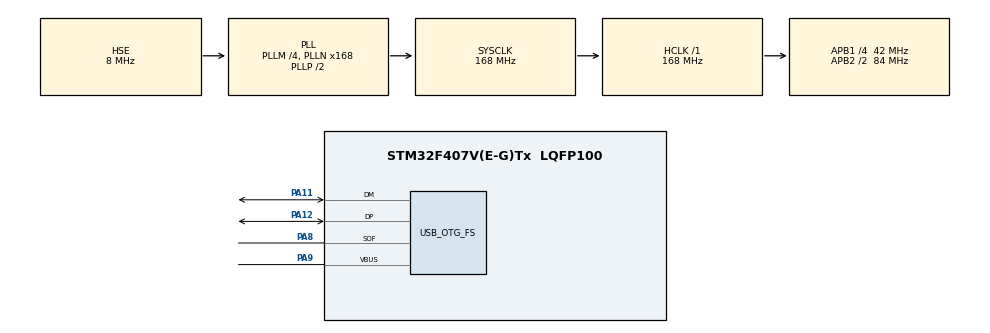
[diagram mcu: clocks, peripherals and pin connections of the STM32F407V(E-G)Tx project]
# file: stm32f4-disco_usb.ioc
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FREERTOS.Tasks01=defaultTask,24,128,StartDefaultTask,Default,NULL,Dynamic,NULL,NULL
FREERTOS.configENABLE_FPU=1
FREERTOS.configTOTAL_HEAP_SIZE=32768
FREERTOS.configUSE_NEWLIB_REENTRANT=1
Mcu.Family=STM32F4
Mcu.Name=STM32F407V(E-G)Tx
Mcu.Package=LQFP100
NVIC.OTG_FS_IRQn=true\:5\:0\:false\:false\:true\:true\:false\:true\:true
NVIC.PriorityGroup=NVIC_PRIORITYGROUP_4
NVIC.TIM1_UP_TIM10_IRQn=true\:15\:0\:false\:false\:true\:false\:false\:true\:true
NVIC.TimeBase=TIM1_UP_TIM10_IRQn
NVIC.TimeBaseIP=TIM1
PA11.Mode=Device_Only
PA11.Signal=USB_OTG_FS_DM
PA12.Mode=Device_Only
PA12.Signal=USB_OTG_FS_DP
PA13.Mode=Serial_Wire
PA13.Signal=SYS_JTMS-SWDIO
PA14.Mode=Serial_Wire
PA14.Signal=SYS_JTCK-SWCLK
PA8.Mode=Activate_SOF_FS
PA8.Signal=USB_OTG_FS_SOF
PA9.Mode=Activate_VBUS
PA9.Signal=USB_OTG_FS_VBUS
PH0-OSC_IN.Mode=HSE-External-Oscillator
PH0-OSC_IN.Signal=RCC_OSC_IN
PH1-OSC_OUT.Mode=HSE-External-Oscillator
PH1-OSC_OUT.Signal=RCC_OSC_OUT
ProjectManager.HeapSize=0x200
ProjectManager.StackSize=0x400
ProjectManager.TargetToolchain=STM32CubeIDE
RCC.48MHZClocksFreq_Value=48000000
RCC.AHBFreq_Value=168000000
RCC.APB1CLKDivider=RCC_HCLK_DIV4
RCC.APB1Freq_Value=42000000
RCC.APB1TimFreq_Value=84000000
RCC.APB2CLKDivider=RCC_HCLK_DIV2
RCC.APB2Freq_Value=84000000
RCC.APB2TimFreq_Value=168000000
RCC.CortexFreq_Value=168000000
RCC.HCLKFreq_Value=168000000
RCC.HSE_VALUE=8000000
RCC.HSI_VALUE=16000000
RCC.LSE_VALUE=32768
RCC.PLLM=4
RCC.PLLN=168
RCC.PLLQ=7
RCC.SYSCLKFreq_VALUE=168000000
RCC.SYSCLKSource=RCC_SYSCLKSOURCE_PLLCLK
RCC.VCOOutputFreq_Value=336000000
USB_DEVICE.CLASS_NAME_FS=CDC
USB_DEVICE.VirtualMode-CDC_FS=Cdc
USB_DEVICE.VirtualModeFS=Cdc_FS
USB_OTG_FS.VirtualMode=Device_Only
VP_FREERTOS_VS_CMSIS_V2.Mode=CMSIS_V2
VP_SYS_VS_tim1.Mode=TIM1
VP_USB_DEVICE_VS_USB_DEVICE_CDC_FS.Mode=CDC_FS
board=custom

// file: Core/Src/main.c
/* USER CODE BEGIN Header */
/**
  ******************************************************************************
  * @file           : main.c
  * @brief          : Main program body
  ******************************************************************************
  * @attention
  *
  * Copyright (c) 2022 STMicroelectronics.
  * All rights reserved.
  *
  * This software is licensed under terms that can be found in the LICENSE file
  * in the root directory of this software component.
  * If no LICENSE file comes with this software, it is provided AS-IS.
  *
  ******************************************************************************
  */
/* USER CODE END Header */
#include "main.h"
#include "cmsis_os.h"
#include "usb_device.h"

/* USER CODE BEGIN Includes */
#include "usbd_cdc_if.h"
#include "cli.h"
/* USER CODE END Includes */

/* Definitions for defaultTask */
osThreadId_t defaultTaskHandle;
const osThreadAttr_t defaultTask_attributes = {
  .name = "defaultTask",
  .stack_size = 512 * 4,
  .priority = (osPriority_t) osPriorityNormal,
};

void SystemClock_Config(void);
static void MX_GPIO_Init(void);
void StartDefaultTask(void *argument);

int main(void)
{

  /* MCU Configuration--------------------------------------------------------*/

  /* Reset of all peripherals, Initializes the Flash interface and the Systick. */
  HAL_Init();

  /* Configure the system clock */
  SystemClock_Config();

  /* Initialize all configured peripherals */
  MX_GPIO_Init();

  /* Init scheduler */
  osKernelInitialize();

  /* Create the thread(s) */
  /* creation of defaultTask */
  defaultTaskHandle = osThreadNew(vCommandConsoleTask, NULL, &defaultTask_attributes);
  //defaultTaskHandle = osThreadNew(StartDefaultTask, NULL, &defaultTask_attributes);

  /* Start scheduler */
  osKernelStart();

  /* We should never get here as control is now taken by the scheduler */
  /* Infinite loop */
  while (1)
  {

  }
}

void SystemClock_Config(void)
{
  RCC_OscInitTypeDef RCC_OscInitStruct = {0};
  RCC_ClkInitTypeDef RCC_ClkInitStruct = {0};

  /** Configure the main internal regulator output voltage
  */
  __HAL_RCC_PWR_CLK_ENABLE();
  __HAL_PWR_VOLTAGESCALING_CONFIG(PWR_REGULATOR_VOLTAGE_SCALE1);

  /** Initializes the RCC Oscillators according to the specified parameters
  * in the RCC_OscInitTypeDef structure.
  */
  RCC_OscInitStruct.OscillatorType = RCC_OSCILLATORTYPE_HSE;
  RCC_OscInitStruct.HSEState = RCC_HSE_ON;
  RCC_OscInitStruct.PLL.PLLState = RCC_PLL_ON;
  RCC_OscInitStruct.PLL.PLLSource = RCC_PLLSOURCE_HSE;
  RCC_OscInitStruct.PLL.PLLM = 4;
  RCC_OscInitStruct.PLL.PLLN = 168;
  RCC_OscInitStruct.PLL.PLLP = RCC_PLLP_DIV2;
  RCC_OscInitStruct.PLL.PLLQ = 7;
  if (HAL_RCC_OscConfig(&RCC_OscInitStruct) != HAL_OK)
  {
    Error_Handler();
  }

  /** Initializes the CPU, AHB and APB buses clocks
  */
  RCC_ClkInitStruct.ClockType = RCC_CLOCKTYPE_HCLK|RCC_CLOCKTYPE_SYSCLK
                              |RCC_CLOCKTYPE_PCLK1|RCC_CLOCKTYPE_PCLK2;
  RCC_ClkInitStruct.SYSCLKSource = RCC_SYSCLKSOURCE_PLLCLK;
  RCC_ClkInitStruct.AHBCLKDivider = RCC_SYSCLK_DIV1;
  RCC_ClkInitStruct.APB1CLKDivider = RCC_HCLK_DIV4;
  RCC_ClkInitStruct.APB2CLKDivider = RCC_HCLK_DIV2;

  if (HAL_RCC_ClockConfig(&RCC_ClkInitStruct, FLASH_LATENCY_5) != HAL_OK)
  {
    Error_Handler();
  }
}

static void MX_GPIO_Init(void)
{

  /* GPIO Ports Clock Enable */
  __HAL_RCC_GPIOH_CLK_ENABLE();
  __HAL_RCC_GPIOA_CLK_ENABLE();

}

/* USER CODE BEGIN 4 */
void init_usb_rtos_obj(void);
BaseType_t CDC_Receiveq_FS(char *data, TickType_t timeout);
uint8_t buffer[128];
uint32_t len = 0;
/* USER CODE END 4 */

void StartDefaultTask(void *argument)
{
  /* init code for USB_DEVICE */
  MX_USB_DEVICE_Init();
  /* USER CODE BEGIN 5 */
  init_usb_rtos_obj();
  uint8_t data[128];
  int qtd;
  /* Infinite loop */
  for(;;)
  {
	//char data;
	//(void)CDC_Receiveq_HS(&data, portMAX_DELAY);
	qtd = receive_usb_data(data, 128, portMAX_DELAY);
	//(void)CDC_Transmit_FS((uint8_t*)&data, 768);
	(void)queue_print_usb(data, qtd, portMAX_DELAY);
  }
  /* USER CODE END 5 */
}

void HAL_TIM_PeriodElapsedCallback(TIM_HandleTypeDef *htim)
{
  if (htim->Instance == TIM1) {
    HAL_IncTick();
  }
}

void Error_Handler(void)
{
  __disable_irq();
  while (1)
  {
  }
}
